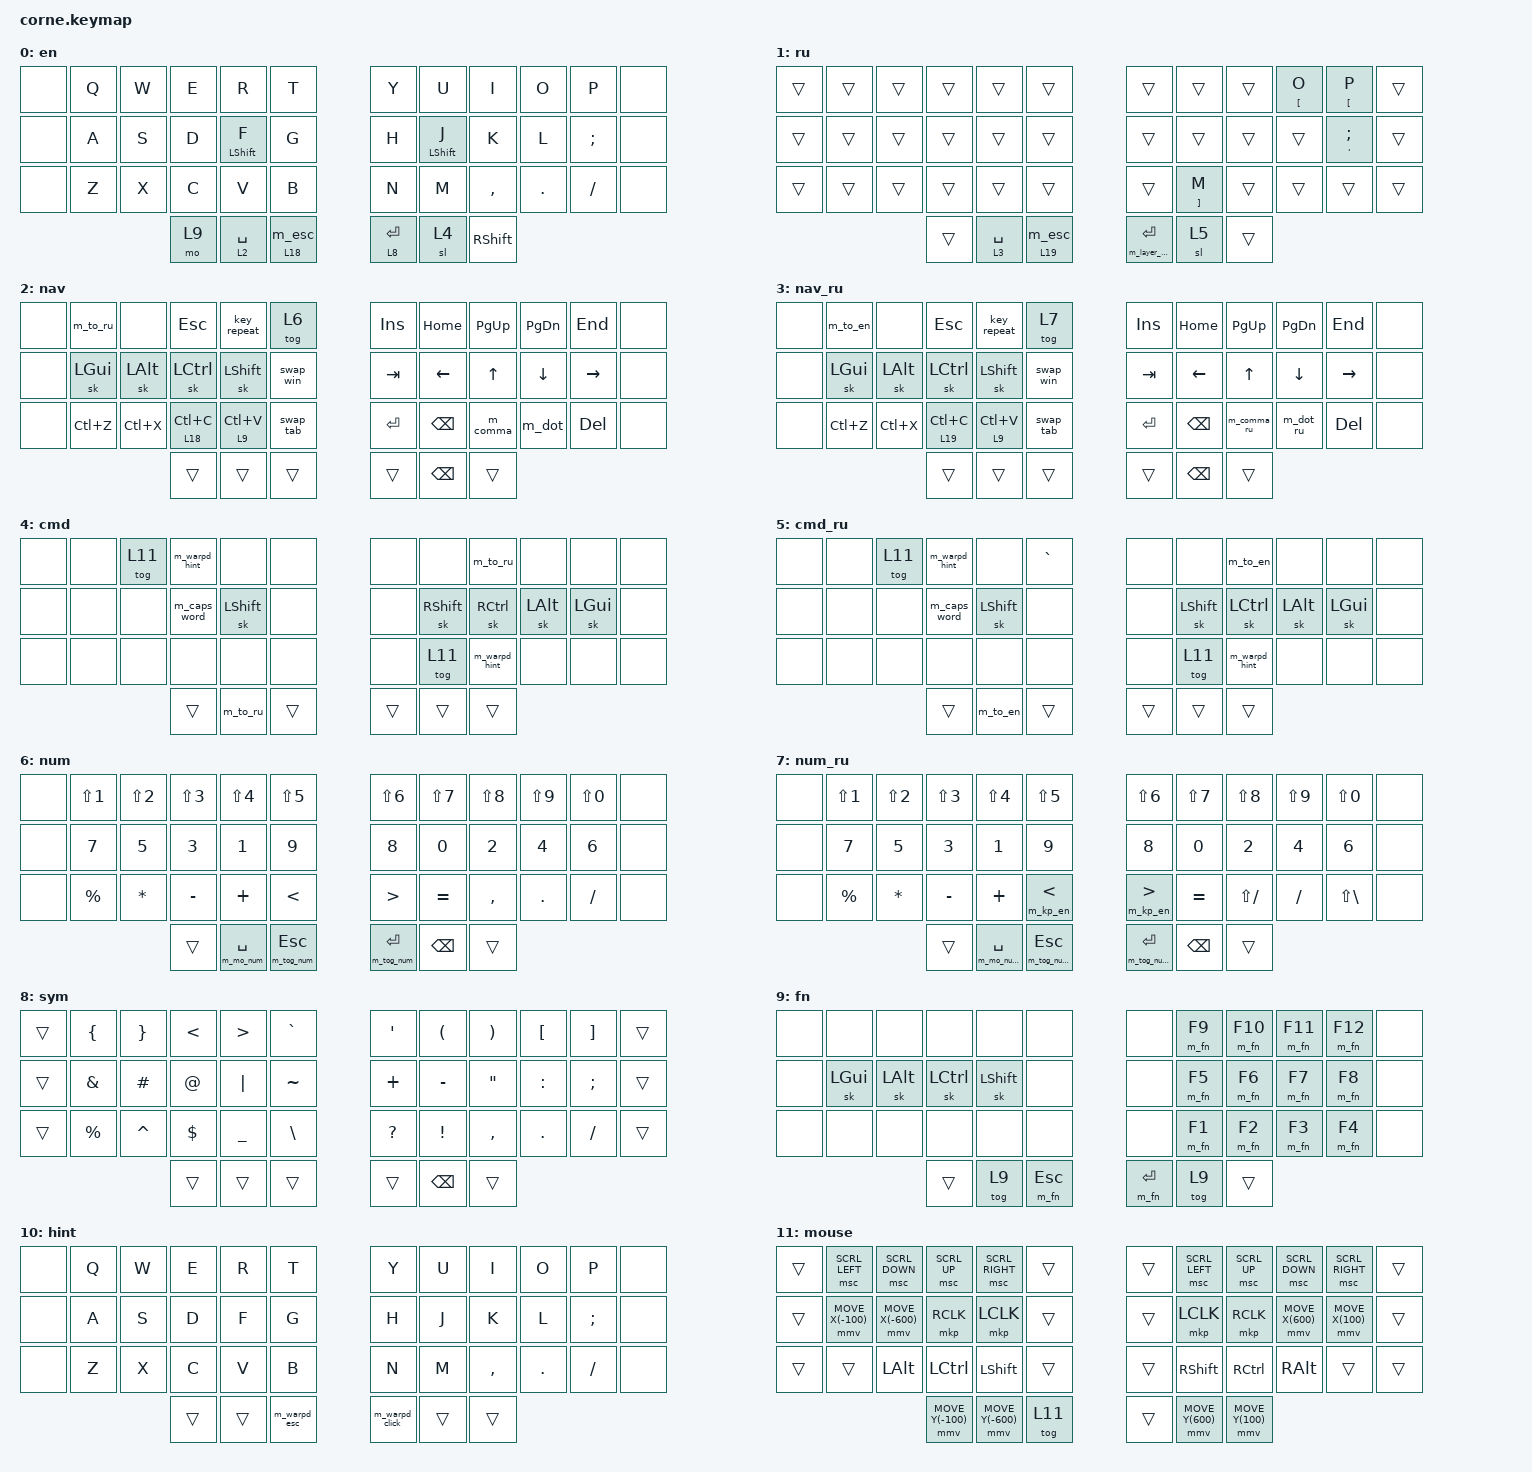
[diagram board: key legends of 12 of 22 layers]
/*
 * Copyright (c) 2020 The ZMK Contributors
 *
 * SPDX-License-Identifier: MIT
 */

#define ZMK_POINTING_DEFAULT_MOVE_VAL 1200  // default: 600
#define ZMK_POINTING_DEFAULT_SCRL_VAL 20    // default: 10

#include <behaviors.dtsi>
#include <dt-bindings/zmk/bt.h>
#include <dt-bindings/zmk/keys.h>
#include <dt-bindings/zmk/pointing.h>

&sk {
    quick-release;
    release-after-ms = <1000>;
};

&sl { release-after-ms = <1000>; };

&lt {
    tapping-term-ms = <200>;
    require-prior-idle-ms = <50>;
};

/ {
    behaviors {
        tp: tap_preferred {
            compatible = "zmk,behavior-hold-tap";
            label = "TAP_PREFERRED";
            #binding-cells = <2>;
            tapping-term-ms = <200>;
            quick-tap-ms = <0>;
            flavor = "tap-preferred";
            bindings = <&kp>, <&kp>;
        };

        swap_win: swapper_win {
            compatible = "zmk,behavior-tri-state";
            label = "SWAPPER_WIN";
            #binding-cells = <0>;
            bindings = <&kt LALT>, <&kp TAB>, <&kt LALT>;

            ignored-key-positions = <4 16 19 20 21 22>;
        };

        swap_tab: swapper_tab {
            compatible = "zmk,behavior-tri-state";
            label = "SWAPPER_TAB";
            #binding-cells = <0>;
            bindings = <&kt LCTRL>, <&kp TAB>, <&kt LCTRL>;

            ignored-key-positions = <4 16 19 20 21 22>;
        };

        lt_sym: lt_sym {
            compatible = "zmk,behavior-hold-tap";
            label = "LT_SYM";
            #binding-cells = <2>;
            tapping-term-ms = <200>;
            flavor = "tap-preferred";
            bindings = <&m_layer_sym>, <&kp>;
        };

        lt_num: lt_num {
            compatible = "zmk,behavior-hold-tap";
            label = "LT_NUM";
            bindings = <&m_mo_num>, <&m_tog_num>;

            #binding-cells = <2>;
            tapping-term-ms = <200>;
            require-prior-idle-ms = <50>;
            flavor = "tap-preferred";
        };

        lt_num_ru: lt_num_ru {
            compatible = "zmk,behavior-hold-tap";
            label = "LT_NUM_RU";
            bindings = <&m_mo_num_ru>, <&m_tog_num_ru>;

            #binding-cells = <2>;
            tapping-term-ms = <200>;
            require-prior-idle-ms = <50>;
            flavor = "tap-preferred";
        };

        lt_esc: lt_esc {
            compatible = "zmk,behavior-hold-tap";
            label = "LT_ESC";
            bindings = <&mo>, <&m_esc>;

            #binding-cells = <2>;
            tapping-term-ms = <200>;
            require-prior-idle-ms = <50>;
            flavor = "tap-preferred";
        };

        tp_warpd_hint: tp_warpd_hint {
            compatible = "zmk,behavior-hold-tap";
            label = "TP_WARPD_HINT";
            #binding-cells = <2>;
            tapping-term-ms = <250>;
            flavor = "tap-preferred";
            bindings = <&m_warpd_hint>, <&kp>;
        };

        tt: tt {
            compatible = "zmk,behavior-hold-tap";
            label = "TT";
            #binding-cells = <2>;
            tapping-term-ms = <250>;
            flavor = "tap-preferred";
            bindings = <&tog>, <&kp>;
        };

        hrm_l: hrm_l {
            compatible = "zmk,behavior-hold-tap";
            label = "HRM_L";
            #binding-cells = <2>;
            tapping-term-ms = <250>;
            quick-tap-ms = <0>;
            flavor = "tap-preferred";
            bindings = <&kp>, <&kp>;

            hold-trigger-key-positions = <6 6 7 8 9 10 11 18 19 20 21 22 23 30 31 32 33 34 35>;
        };

        hrm_r: hrm_r {
            compatible = "zmk,behavior-hold-tap";
            label = "HRM_R";
            #binding-cells = <2>;
            tapping-term-ms = <250>;
            quick-tap-ms = <0>;
            flavor = "tap-preferred";
            bindings = <&kp>, <&kp>;

            hold-trigger-key-positions = <17 0 1 2 3 4 5 12 13 14 15 16 17 24 25 26 27 28 29>;
        };
    };

    macros {
        m_en: m_en {
            compatible = "zmk,behavior-macro";
            #binding-cells = <0>;
            bindings = <&kp CAPS>;
            label = "M_EN";
            wait-ms = <0>;
            tap-ms = <0>;
        };

        m_ru: m_ru {
            compatible = "zmk,behavior-macro";
            #binding-cells = <0>;
            bindings = <&kp LS(CAPS)>;
            label = "M_RU";
            wait-ms = <0>;
            tap-ms = <0>;
        };

        m_to_en: macro_en {
            compatible = "zmk,behavior-macro";
            #binding-cells = <0>;
            bindings = <&to 0 &m_en>;
            label = "MACRO_EN";
            wait-ms = <0>;
            tap-ms = <0>;
        };

        m_to_ru: macro_ru {
            compatible = "zmk,behavior-macro";
            #binding-cells = <0>;
            bindings = <&to 1 &m_ru>;
            label = "MACRO_RU";
            wait-ms = <0>;
            tap-ms = <0>;
        };

        m_kp_en: kp_en {
            compatible = "zmk,behavior-macro-one-param";
            #binding-cells = <1>;
            bindings = <&m_en &macro_param_1to1 &kp MACRO_PLACEHOLDER &m_ru>;
            label = "KP_EN";
            wait-ms = <0>;
            tap-ms = <0>;
        };

        m_comma: m_comma {
            compatible = "zmk,behavior-macro";
            #binding-cells = <0>;
            bindings = <&kp COMMA &kp SPACE>;
            label = "M_COMMA";
            wait-ms = <0>;
            tap-ms = <0>;
        };

        m_comma_ru: m_comma_ru {
            compatible = "zmk,behavior-macro";
            #binding-cells = <0>;
            bindings = <&kp LS(SLASH) &kp SPACE>;
            label = "M_COMMA_RU";
            wait-ms = <0>;
            tap-ms = <0>;
        };

        m_dot: m_dot {
            compatible = "zmk,behavior-macro";
            #binding-cells = <0>;
            bindings = <&kp DOT &kp SPACE &sk LSHFT>;
            label = "M_DOT";
            wait-ms = <0>;
            tap-ms = <0>;
        };

        m_dot_ru: m_dot_ru {
            compatible = "zmk,behavior-macro";
            #binding-cells = <0>;
            bindings = <&kp SLASH &kp SPACE &sk LSHFT>;
            label = "M_DOT_RU";
            wait-ms = <0>;
            tap-ms = <0>;
        };

        m_layer_sym: m_layer_sym {
            compatible = "zmk,behavior-macro";
            #binding-cells = <0>;
            bindings =
                <&m_en>,
                <&macro_press>,
                <&mo 0 &mo 8>,
                <&macro_pause_for_release>,
                <&macro_release>,
                <&mo 8 &mo 0>,
                <&macro_tap>,
                <&m_ru>;

            label = "M_LAYER_SYM";
            wait-ms = <0>;
            tap-ms = <0>;
        };

        m_layer_cmd: macro_layer_cmd {
            compatible = "zmk,behavior-macro";
            #binding-cells = <0>;
            bindings =
                <&m_en>,
                <&macro_press>,
                <&mo 0 &mo 4>,
                <&macro_pause_for_release>,
                <&macro_release>,
                <&mo 4 &mo 0>,
                <&macro_tap>,
                <&m_ru>;

            label = "MACRO_LAYER_CMD";
            wait-ms = <0>;
            tap-ms = <0>;
        };

        m_warpd_hint: macro_warpd_hint {
            compatible = "zmk,behavior-macro";
            #binding-cells = <0>;
            bindings = <&kp F17 &tog 10>;
            label = "MACRO_WARPD_HINT";
            wait-ms = <0>;
            tap-ms = <0>;
        };

        m_warpd_esc: macro_warpd_esc {
            compatible = "zmk,behavior-macro";
            #binding-cells = <0>;
            bindings = <&kp ESC &tog 10>;
            label = "MACRO_WARPD_ESC";
            wait-ms = <0>;
            tap-ms = <0>;
        };

        m_warpd_click: macro_warpd_click {
            compatible = "zmk,behavior-macro";
            #binding-cells = <0>;
            bindings = <&kp ESC &mkp LCLK &tog 10>;
            label = "MACRO_WARPD_CLICK";
            wait-ms = <0>;
            tap-ms = <0>;
        };

        m_warpd_normal: macro_warpd_normal {
            compatible = "zmk,behavior-macro";
            #binding-cells = <0>;
            bindings = <&kp F18 &tog 10>;
            label = "MACRO_WARPD_NORMAL";
            wait-ms = <0>;
            tap-ms = <0>;
        };

        m_zed_1: macro_zed_1 {
            compatible = "zmk,behavior-macro";
            #binding-cells = <0>;
            bindings = <&kp F3 &kp LA(UP) &kp DOWN>;
            label = "MACRO_ZED_1";
            wait-ms = <0>;
            tap-ms = <0>;
        };

        m_caps_word: macro_caps_word {
            compatible = "zmk,behavior-macro";
            #binding-cells = <0>;
            bindings = <&kp LSHFT &caps_word>;
            label = "MACRO_CAPS_WORD";
            wait-ms = <0>;
            tap-ms = <0>;
        };

        m_fn: macro_fn {
            compatible = "zmk,behavior-macro-one-param";
            #binding-cells = <1>;
            bindings = <&tog 9 &macro_param_1to1 &kp MACRO_PLACEHOLDER>;
            label = "MACRO_FN";
            wait-ms = <0>;
            tap-ms = <0>;
        };

        m_tog_num: tog_multi {
            compatible = "zmk,behavior-macro-one-param";
            #binding-cells = <1>;
            bindings = <&tog 6 &macro_param_1to1 &kp MACRO_PLACEHOLDER>;
            label = "TOG_MULTI";
            wait-ms = <0>;
            tap-ms = <0>;
        };

        m_tog_num_ru: tog_multi_ru {
            compatible = "zmk,behavior-macro-one-param";
            #binding-cells = <1>;
            bindings = <&tog 7 &macro_param_1to1 &kp MACRO_PLACEHOLDER>;
            label = "TOG_MULTI_RU";
            wait-ms = <0>;
            tap-ms = <0>;
        };

        m_mo_num: mo_multi {
            compatible = "zmk,behavior-macro";
            #binding-cells = <0>;
            bindings =
                <&tog 6>,
                <&macro_press>,
                <&mo 2>,
                <&macro_pause_for_release>,
                <&macro_release>,
                <&mo 2>;

            label = "MO_MULTI";
            wait-ms = <0>;
            tap-ms = <0>;
        };

        m_mo_num_ru: mo_multi_ru {
            compatible = "zmk,behavior-macro";
            #binding-cells = <0>;
            bindings =
                <&tog 7>,
                <&macro_press>,
                <&mo 3>,
                <&macro_pause_for_release>,
                <&macro_release>,
                <&mo 3>;

            label = "MO_MULTI_RU";
            wait-ms = <0>;
            tap-ms = <0>;
        };

        m_esc: m_esc {
            compatible = "zmk,behavior-macro";
            #binding-cells = <0>;
            bindings =
                <&macro_press>,
                <&kp ESC>,
                <&macro_pause_for_release>,
                <&macro_release>,
                <&kp ESC &kp LSHFT &kp LCTRL &kp LALT &kp LGUI>;

            label = "M_ESC";
        };
    };

    combos {
        compatible = "zmk,combos";

        combo_esc {
            bindings = <&kp ESC>;
            key-positions = <>;
        };

        combo_ret {
            bindings = <&kp RET>;
            key-positions = <>;
        };

        combo_bs {
            bindings = <&kp BACKSPACE>;
            key-positions = <18 19>;
        };

        combo_spc {
            bindings = <&kp SPACE>;
            key-positions = <>;
        };

        combo_caps_word {
            bindings = <&caps_word>;
            key-positions = <21 9>;
        };

        combo_mouse_l {
            bindings = <&tog 14>;
            key-positions = <>;
            layers = <2 3 0 1>;
        };

        combo_mouse_r {
            bindings = <&tog 14>;
            key-positions = <>;
            layers = <2 3 0 1>;
        };

        combo_bootloader_l {
            bindings = <&bootloader>;
            key-positions = <0 12>;
        };

        combo_bootloader_r {
            bindings = <&bootloader>;
            key-positions = <11 23>;
        };

        fn {
            bindings = <&mo 9>;
            key-positions = <37 38>;
            layers = <0 1>;
            timeout-ms = <150>;
            require-prior-idle-ms = <50>;
        };
    };

    keymap {
        compatible = "zmk,keymap";

        en {
            // -----------------------------------------------------------------------------------------
            // | TAB  |  Q  |  W  |  E  |  R  |    T    |   |  Y  |  U   |  I  |  O  |  P  | ESC |
            // | CTRL |  A  |  S  |  D  |  F  |    G    |   |  H  |  J   |  K  |  L  |  ;  |  LWR/'   |
            // | SHFT |  Z  |  X  |  C  |  V  |    B    |   |  N  |  M   |  ,  |  .  |  /  | SHFT |
            //                    | GUI | LWR | ALT/ENT |   | HYPER/SPC | BKSP  | RSE |

            bindings = <
&none  &kp Q  &kp W  &kp E  &kp R           &kp T           &kp Y        &kp U           &kp I      &kp O    &kp P     &none
&none  &kp A  &kp S  &kp D  &hrm_l LSHFT F  &kp G           &kp H        &hrm_r LSHFT J  &kp K      &kp L    &kp SEMI  &none
&none  &kp Z  &kp X  &kp C  &kp V           &kp B           &kp N        &kp M           &kp COMMA  &kp DOT  &kp FSLH  &none
                     &mo 9  &lt 2 SPACE     &lt_esc 18 0    &lt 8 ENTER  &sl 4           &kp RSHFT
            >;
        };

        ru {
            bindings = <
&trans  &trans  &trans  &trans  &trans       &trans          &trans           &trans      &trans  &tp LBKT O  &tp LBKT P    &trans
&trans  &trans  &trans  &trans  &trans       &trans          &trans           &trans      &trans  &trans      &tp SQT SEMI  &trans
&trans  &trans  &trans  &trans  &trans       &trans          &trans           &tp RBKT M  &trans  &trans      &trans        &trans
                        &trans  &lt 3 SPACE  &lt_esc 19 0    &lt_sym 0 ENTER  &sl 5       &trans
            >;
        };

        nav {
            bindings = <
&none  &m_to_ru      &none      &kp ESCAPE    &key_repeat  &tog 6       &kp INS  &kp HOME       &kp PG_UP  &kp PG_DN  &kp END    &none
&none  &sk LEFT_GUI  &sk LALT   &sk LCTRL     &sk LSHFT    &swap_win    &kp TAB  &kp LEFT       &kp UP     &kp DOWN   &kp RIGHT  &none
&none  &kp LC(Z)     &kp LC(X)  &lt 18 LC(C)  &tt 9 LC(V)  &swap_tab    &kp RET  &kp BACKSPACE  &m_comma   &m_dot     &kp DEL    &none
                                &trans        &trans       &trans       &trans   &kp BACKSPACE  &trans
            >;
        };

        nav_ru {
            bindings = <
&none  &m_to_en      &none      &kp ESCAPE    &key_repeat  &tog 7       &kp INS  &kp HOME       &kp PG_UP    &kp PG_DN  &kp END    &none
&none  &sk LEFT_GUI  &sk LALT   &sk LCTRL     &sk LSHFT    &swap_win    &kp TAB  &kp LEFT       &kp UP       &kp DOWN   &kp RIGHT  &none
&none  &kp LC(Z)     &kp LC(X)  &lt 19 LC(C)  &tt 9 LC(V)  &swap_tab    &kp RET  &kp BACKSPACE  &m_comma_ru  &m_dot_ru  &kp DEL    &none
                                &trans        &trans       &trans       &trans   &kp BACKSPACE  &trans
            >;
        };

        cmd {
            bindings = <
&none  &none  &tog 11  &m_warpd_hint  &none      &none     &none   &none      &m_to_ru       &none     &none     &none
&none  &none  &none    &m_caps_word   &sk LSHFT  &none     &none   &sk RSHFT  &sk RCTRL      &sk LALT  &sk LGUI  &none
&none  &none  &none    &none          &none      &none     &none   &tog 11    &m_warpd_hint  &none     &none     &none
                       &trans         &m_to_ru   &trans    &trans  &trans     &trans
            >;
        };

        cmd_ru {
            bindings = <
&none  &none  &tog 11  &m_warpd_hint  &none      &kp GRAVE    &none   &none      &m_to_en       &none     &none     &none
&none  &none  &none    &m_caps_word   &sk LSHFT  &none        &none   &sk LSHFT  &sk LCTRL      &sk LALT  &sk LGUI  &none
&none  &none  &none    &none          &none      &none        &none   &tog 11    &m_warpd_hint  &none     &none     &none
                       &trans         &m_to_en   &trans       &trans  &trans     &trans
            >;
        };

        num {
            bindings = <
&none  &kp LS(N1)   &kp LS(N2)    &kp LS(N3)  &kp LS(N4)       &kp LS(N5)        &kp LS(N6)      &kp LS(N7)     &kp LS(N8)  &kp LS(N9)  &kp LS(N0)  &none
&none  &kp N7       &kp N5        &kp N3      &kp N1           &kp N9            &kp N8          &kp N0         &kp N2      &kp N4      &kp N6      &none
&none  &kp PERCENT  &kp ASTERISK  &kp MINUS   &kp PLUS         &kp LT            &kp GT          &kp EQUAL      &kp COMMA   &kp DOT     &kp SLASH   &none
                                  &trans      &lt_num 0 SPACE  &m_tog_num ESC    &m_tog_num RET  &kp BACKSPACE  &trans
            >;
        };

        num_ru {
            bindings = <
&none  &kp LS(N1)   &kp LS(N2)    &kp LS(N3)  &kp LS(N4)          &kp LS(N5)           &kp LS(N6)         &kp LS(N7)     &kp LS(N8)     &kp LS(N9)  &kp LS(N0)         &none
&none  &kp N7       &kp N5        &kp N3      &kp N1              &kp N9               &kp N8             &kp N0         &kp N2         &kp N4      &kp N6             &none
&none  &kp PERCENT  &kp ASTERISK  &kp MINUS   &kp PLUS            &m_kp_en LT          &m_kp_en GT        &kp EQUAL      &kp LS(SLASH)  &kp SLASH   &kp LS(BACKSLASH)  &none
                                  &trans      &lt_num_ru 0 SPACE  &m_tog_num_ru ESC    &m_tog_num_ru RET  &kp BACKSPACE  &trans
            >;
        };

        sym {
            bindings = <
&trans  &kp LEFT_BRACE  &kp RIGHT_BRACE  &kp LT       &kp GT          &kp GRAVE        &kp SQT       &kp LPAR         &kp RIGHT_PARENTHESIS  &kp LEFT_BRACKET  &kp RIGHT_BRACKET  &trans
&trans  &kp AMPERSAND   &kp HASH         &kp AT_SIGN  &kp PIPE        &kp TILDE        &kp PLUS      &kp MINUS        &kp DQT                &kp COLON         &kp SEMI           &trans
&trans  &kp PERCENT     &kp CARET        &kp DOLLAR   &kp UNDERSCORE  &kp BACKSLASH    &kp QUESTION  &kp EXCLAMATION  &kp COMMA              &kp DOT           &kp SLASH          &trans
                                         &trans       &trans          &trans           &trans        &kp BACKSPACE    &trans
            >;
        };

        fn {
            bindings = <
&none  &none     &none     &none      &none      &none        &none      &m_fn F9  &m_fn F10  &m_fn F11  &m_fn F12  &none
&none  &sk LGUI  &sk LALT  &sk LCTRL  &sk LSHFT  &none        &none      &m_fn F5  &m_fn F6   &m_fn F7   &m_fn F8   &none
&none  &none     &none     &none      &none      &none        &none      &m_fn F1  &m_fn F2   &m_fn F3   &m_fn F4   &none
                           &trans     &tog 9     &m_fn ESC    &m_fn RET  &tog 9    &trans
            >;
        };

        hint {
            bindings = <
&none  &kp Q  &kp W  &kp E   &kp R   &kp T           &kp Y           &kp U   &kp I      &kp O       &kp P          &none
&none  &kp A  &kp S  &kp D   &kp F   &kp G           &kp H           &kp J   &kp K      &kp L       &kp SEMICOLON  &none
&none  &kp Z  &kp X  &kp C   &kp V   &kp B           &kp N           &kp M   &kp COMMA  &kp PERIOD  &kp SLASH      &none
                     &trans  &trans  &m_warpd_esc    &m_warpd_click  &trans  &trans
            >;
        };

        mouse {
            bindings = <
&trans  &msc SCRL_LEFT     &msc SCRL_DOWN     &msc SCRL_UP       &msc SCRL_RIGHT    &trans     &trans  &msc SCRL_LEFT    &msc SCRL_UP      &msc SCRL_DOWN    &msc SCRL_RIGHT   &trans
&trans  &mmv MOVE_X(-100)  &mmv MOVE_X(-600)  &mkp RCLK          &mkp LCLK          &trans     &trans  &mkp LCLK         &mkp RCLK         &mmv MOVE_X(600)  &mmv MOVE_X(100)  &trans
&trans  &trans             &kp LALT           &kp LCTRL          &kp LSHFT          &trans     &trans  &kp RSHFT         &kp RCTRL         &kp RALT          &trans            &trans
                                              &mmv MOVE_Y(-100)  &mmv MOVE_Y(-600)  &tog 11    &trans  &mmv MOVE_Y(600)  &mmv MOVE_Y(100)
            >;
        };

        sys {
            bindings = <
&bootloader  &trans  &trans  &trans  &trans  &trans    &trans  &trans  &trans  &trans  &trans  &bootloader
&trans       &trans  &trans  &trans  &trans  &trans    &trans  &trans  &trans  &trans  &trans  &trans
&trans       &trans  &trans  &trans  &trans  &trans    &trans  &trans  &trans  &trans  &trans  &trans
                             &trans  &trans  &trans    &trans  &trans  &trans
            >;
        };

        mouse_l {
            bindings = <
&none   &msc SCRL_LEFT     &msc SCRL_DOWN    &msc SCRL_UP       &msc SCRL_RIGHT   &none      &none  &none      &none      &none      &none          &none
&none   &mmv MOVE_LEFT     &mmv MOVE_DOWN    &mmv MOVE_UP       &mmv MOVE_RIGHT   &none      &none  &mkp LCLK  &mkp RCLK  &mkp MB3   &m_warpd_hint  &none
&kp N8  &mmv MOVE_X(-200)  &mmv MOVE_Y(200)  &mmv MOVE_Y(-200)  &mmv MOVE_X(200)  &none      &none  &mkp LCLK  &kp LSHFT  &kp LCTRL  &kp LALT       &none
                                             &none              &none             &tog 13    &none  &none      &none
            >;
        };

        mouse_r {
            bindings = <
&trans  &none          &none      &none      &none      &trans     &trans  &msc SCRL_LEFT     &msc SCRL_UP       &msc SCRL_DOWN    &msc SCRL_RIGHT   &trans
&trans  &m_warpd_hint  &mkp MB3   &mkp RCLK  &mkp LCLK  &trans     &trans  &mmv MOVE_LEFT     &mmv MOVE_UP       &mmv MOVE_DOWN    &mmv MOVE_RIGHT   &trans
&kp N9  &kp LALT       &kp LCTRL  &kp LSHFT  &mkp LCLK  &trans     &trans  &mmv MOVE_X(-200)  &mmv MOVE_Y(-200)  &mmv MOVE_Y(200)  &mmv MOVE_X(200)  &trans
                                  &none      &none      &tog 14    &trans  &none              &none
            >;
        };

        lo {
            bindings = <
&trans  &trans  &trans  &trans  &trans  &trans    &trans      &trans      &trans      &trans      &trans      &trans
&trans  &trans  &trans  &trans  &trans  &trans    &kp LC(N0)  &kp LC(N1)  &kp LC(N2)  &kp LC(N3)  &kp LC(N4)  &trans
&trans  &trans  &trans  &trans  &trans  &trans    &trans      &trans      &trans      &trans      &trans      &trans
                        &trans  &trans  &trans    &trans      &trans      &trans
            >;
        };

        alt {
            bindings = <
&none  &none  &none  &none   &none   &none     &kp TILDE     &kp EQUAL        &kp DQT    &kp HASH       &kp GRAVE  &none
&none  &none  &none  &none   &none   &none     &kp PLUS      &kp MINUS        &kp COLON  &kp SEMICOLON  &kp SQT    &none
&none  &none  &none  &none   &none   &none     &kp QUESTION  &kp EXCLAMATION  &trans     &trans         &trans     &none
                     &trans  &trans  &trans    &trans        &trans           &trans
            >;
        };

        alt_ru {
            bindings = <
&none  &none  &none  &none   &none   &none     &kp GRAVE   &kp EQUAL        &kp LS(N2)     &kp LS(N3)  &kp LBKT  &none
&none  &none  &none  &none   &none   &none     &kp PLUS    &kp MINUS        &kp LS(N6)     &kp LS(N4)  &kp SQT   &none
&none  &none  &none  &none   &none   &none     &kp LS(N7)  &kp EXCLAMATION  &kp LS(SLASH)  &kp SLASH   &kp RBKT  &none
                     &trans  &trans  &trans    &trans      &trans           &trans
            >;
        };

        num_ {
            bindings = <
&none  &none     &kp BACKSPACE  &kp ESC    &kp DEL     &none        &kp SLASH   &kp N9         &kp N0  &kp MINUS  &kp EQUAL  &none
&none  &kp LGUI  &kp LALT       &kp LCTRL  &kp LSHIFT  &kp EQUAL    &kp PERIOD  &kp N5         &kp N6  &kp N7     &kp N8     &none
&none  &kp LALT  &kp LCTRL      &none      &kp LSHIFT  &kp SPACE    &kp COMMA   &kp N1         &kp N2  &kp N3     &kp N4     &none
                                &trans     &trans      &trans       &trans      &kp BACKSPACE  &trans
            >;
        };

        num_ru_ {
            bindings = <
&none  &none     &kp BACKSPACE  &kp ESC    &kp DEL    &none        &kp LS(BACKSLASH)  &kp N9         &kp N0  &kp MINUS  &kp EQUAL  &none
&none  &kp LGUI  &kp LALT       &kp LCTRL  &kp LSHFT  &kp EQUAL    &kp SLASH          &kp N5         &kp N6  &kp N7     &kp N8     &none
&none  &kp LALT  &kp LCTRL      &none      &kp LSHFT  &kp SPACE    &kp LS(SLASH)      &kp N1         &kp N2  &kp N3     &kp N4     &none
                                &trans     &trans     &trans       &trans             &kp BACKSPACE  &trans
            >;
        };

        layer_below {
            // -----------------------------------------------------------------------------------------
            // |      |  !  |  @  |  #  |  $  |    %     |   |  ^  |  &  |  *  |  (  |  )  |   \   |
            // |      |  1  |  2  |  3  |  4  |    5     |   |  -  |  =  |  `  |  [  |  ]  |  "|"  |
            // | SHFT |  6  |  7  |  8  |  9  |    0     |   |  _  |  +  |  ~  |  {  |  }  | RSHFT |
            //                     | GUI |     | ALT/ENT |   | HYPER/SPACE | BKSP |    |

            bindings = <
&trans     &kp EXCL  &kp AT  &kp HASH  &kp DLLR  &kp PRCNT       &kp CARET                   &kp AMPS   &kp KP_MULTIPLY  &kp LPAR  &kp RPAR  &kp BSLH
&trans     &kp N1    &kp N2  &kp N3    &kp N4    &kp N5          &kp MINUS                   &kp EQUAL  &kp GRAVE        &kp LBKT  &kp RBKT  &kp PIPE
&kp LSHFT  &kp N6    &kp N7  &kp N8    &kp N9    &kp N0          &kp UNDER                   &kp PLUS   &kp TILDE        &kp LBRC  &kp RBRC  &kp RSHFT
                             &kp LGUI  &trans    &tp LALT RET    &tp LC(LS(LA(LGUI))) SPACE  &kp BSPC   &trans
            >;
        };

        layer_above {
            // -----------------------------------------------------------------------------------------
            // |       |  F1  |  F2  |  F3  |  F4  |  F5 |            |  F6  |  F7  |  F8  |  F9  |  F10  |   |
            // |       | Prev | Next | Vol - | Vol + | Play/Pause |   |      | LFT | DWN |  UP | RGT |     |     |
            // | BTCLR | BT1 | BT2 | BT3 | BT4 | BT5 |   |            |     |     |     |     |     |     |
            //                    |     |     |    |                  |     |     |     |

            bindings = <
&trans      &kp F1        &kp F2        &kp F3        &kp F4        &kp F5          &kp F6    &kp F7    &kp F8  &kp F9     &kp F10  &trans
&trans      &kp C_PREV    &kp C_NEXT    &kp C_VOL_DN  &kp C_VOL_UP  &kp C_PP        &kp LEFT  &kp DOWN  &kp UP  &kp RIGHT  &trans   &trans
&bt BT_CLR  &bt BT_SEL 0  &bt BT_SEL 1  &bt BT_SEL 2  &bt BT_SEL 3  &bt BT_SEL 4    &trans    &trans    &trans  &trans     &trans   &trans
                                        &trans        &trans        &trans          &trans    &trans    &trans
            >;
        };
    };

    conditional_layers { compatible = "zmk,conditional-layers"; };
};
